# NAVSS0_SPINLOCK_0_SPINLOCK register map
Vendor: Texas Instruments
Peripheral module from a debugger description file (folder J721S2).
Registers are 32-bit, read-only, reset 0x0 unless marked. A register's access mark holds for its fields unless they carry their own. Offsets are as the file gives them; lines under a group give offsets from that group; [hi:lo] are bit positions; {n}, {i} and the like mark numbered series; 'fields as' and 'values as' point back to an identical list; <NAME> marks a mode.

## NAVSS0_SPINLOCK_0_SPINLOCK
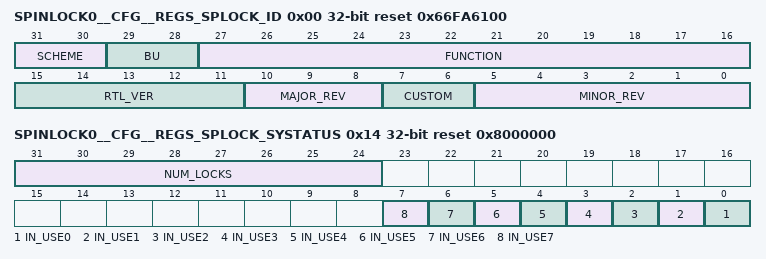
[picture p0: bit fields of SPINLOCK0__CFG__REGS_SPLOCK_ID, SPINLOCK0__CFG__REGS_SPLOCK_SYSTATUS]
0x00 SPINLOCK0__CFG__REGS_SPLOCK_ID reset 0x66FA6100 — This is the standard TI peripheral ID register that exists at address 0 in the peripheral space
  [31:30] SCHEME — Used to distinguish which ID numbering scheme is used.
  [29:28] BU — BU identifier
  [27:16] FUNCTION — Module family.
  [15:11] RTL_VER — RTL version. R of X.Y.R.Z
  [10:8] MAJOR_REV — Major revision. X of X.Y.R.Z
  [7:6] CUSTOM — Special version number
  [5:0] MINOR_REV — Minor revision. Y of X.Y.R.Z
0x10 SPINLOCK0__CFG__REGS_SPLOCK_SYSCONFIG rw — Provides the SOFTRESET register for backwards compatibility with OMAP Spinlock
  [1] SOFT_RESET — Module Software Reset The bit is automatically reset by the hardware. During reads, it always returns 0 It has the same effect as the hardware reset Writing a 0 has no effect. Writing a 1 will start a soft reset sequence and free all of the locks
0x14 SPINLOCK0__CFG__REGS_SPLOCK_SYSTATUS reset 0x8000000 — Provides information about the Spinlock module
  [31:24] NUM_LOCKS — Module configuration parameter n, the total number of spinlocks divided by 32. e.g. For 256 spin locks, this will return the number 0x08
  [n] IN_USE{n} (n=0..7) — In-Use flag {n} covering lock registers {32n} - {32n+31}. If no lock registers are implemented in this range, then this flag always reads as 0 Read 0 : All lock registers {32n} - {32n+31} are in the Not Taken state Read 1 : At least one of the lock registers {32n} - {32n+31} are in the Taken state
0x800 SPINLOCK0__CFG__REGS_LOCK rw — The Lock[a] register is read and written to perform lock and unlock operations on lock 'a'
  [0] TAKEN — Lock Status Read 0 : Lock was previously free. The reader now has been granted the lock. Read 1 : Lock was previously taken. The reader has not been granted the lock and must retry. Write 0 : Free the lock by setting TAKEN to zero. Write 1 : No effect
